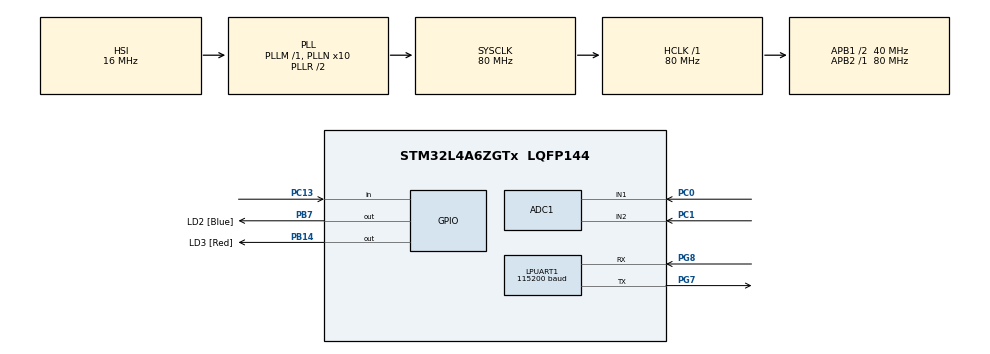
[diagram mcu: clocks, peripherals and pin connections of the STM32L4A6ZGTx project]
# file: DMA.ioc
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ADC1.Channel-2\#ChannelRegularConversion=ADC_CHANNEL_1
ADC1.ContinuousConvMode=ENABLE
ADC1.NbrOfConversionFlag=1
ADC1.OffsetNumber-2\#ChannelRegularConversion=ADC_OFFSET_NONE
ADC1.Rank-2\#ChannelRegularConversion=1
ADC1.SamplingTime-2\#ChannelRegularConversion=ADC_SAMPLETIME_2CYCLES_5
ADC1.SingleDiff-2\#ChannelRegularConversion=ADC_DIFFERENTIAL_ENDED
ADC1.master=1
Dma.ADC1.0.Direction=DMA_PERIPH_TO_MEMORY
Dma.ADC1.0.Instance=DMA1_Channel1
Dma.ADC1.0.MemDataAlignment=DMA_MDATAALIGN_HALFWORD
Dma.ADC1.0.MemInc=DMA_MINC_ENABLE
Dma.ADC1.0.Mode=DMA_NORMAL
Dma.ADC1.0.PeriphDataAlignment=DMA_PDATAALIGN_HALFWORD
Dma.ADC1.0.PeriphInc=DMA_PINC_DISABLE
Dma.ADC1.0.Priority=DMA_PRIORITY_LOW
Dma.Request0=ADC1
LPUART1.BaudRate=115200
LPUART1.WordLength=UART_WORDLENGTH_8B
Mcu.Family=STM32L4
Mcu.Name=STM32L4A6ZGTx
Mcu.Package=LQFP144
NVIC.DMA1_Channel1_IRQn=true\:0\:0\:false\:false\:true\:false\:true\:true
NVIC.PriorityGroup=NVIC_PRIORITYGROUP_4
PB14.GPIO_Label=LD3 [Red]
PB14.PinState=GPIO_PIN_SET
PB14.Signal=GPIO_Output
PB7.GPIO_Label=LD2 [Blue]
PB7.PinState=GPIO_PIN_SET
PB7.Signal=GPIO_Output
PC0.Signal=ADCx_IN1
PC1.Signal=ADCx_IN2
PC13.Signal=GPIO_Input
PC14-OSC32_IN\ (PC14).Mode=LSE-External-Oscillator
PC14-OSC32_IN\ (PC14).Signal=RCC_OSC32_IN
PC15-OSC32_OUT\ (PC15).Mode=LSE-External-Oscillator
PC15-OSC32_OUT\ (PC15).Signal=RCC_OSC32_OUT
PG7.Mode=Asynchronous
PG7.Signal=LPUART1_TX
PG8.Mode=Asynchronous
PG8.Signal=LPUART1_RX
ProjectManager.HeapSize=0x200
ProjectManager.StackSize=0x400
ProjectManager.TargetToolchain=STM32CubeIDE
RCC.ADCFreq_Value=64000000
RCC.AHBFreq_Value=80000000
RCC.APB1CLKDivider=RCC_HCLK_DIV2
RCC.APB1Freq_Value=40000000
RCC.APB1TimFreq_Value=80000000
RCC.APB2Freq_Value=80000000
RCC.APB2TimFreq_Value=80000000
RCC.CortexFreq_Value=80000000
RCC.FLatency=FLASH_LATENCY_4
RCC.HCLKFreq_Value=80000000
RCC.HSE_VALUE=8000000
RCC.HSI48_VALUE=48000000
RCC.HSI_VALUE=16000000
RCC.MSI_VALUE=4000000
RCC.PLLN=10
RCC.PLLSourceVirtual=RCC_PLLSOURCE_HSI
RCC.SYSCLKFreq_VALUE=80000000
RCC.SYSCLKSource=RCC_SYSCLKSOURCE_PLLCLK
RCC.USBFreq_Value=64000000
RCC.VCOOutputFreq_Value=160000000
SH.ADCx_IN1.0=ADC1_IN1,IN1-Differential
SH.ADCx_IN2.0=ADC1_IN2,IN1-Differential
board=NUCLEO-L4A6ZG

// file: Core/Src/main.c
#include "main.h"
#include <stdio.h>
#include <string.h>

ADC_HandleTypeDef hadc1;
DMA_HandleTypeDef hdma_adc1;
UART_HandleTypeDef hlpuart1;

/* USER CODE BEGIN PV */
uint32_t adc_values[1000];
char msg[50];
/* USER CODE END PV */

float calculate_average(uint32_t *array, size_t length) {
    uint64_t sum = 0;
    for (size_t i = 0; i < length; i++) {
        sum += array[i];
    }
    return (float)sum / length;
}

void SystemClock_Config(void);
void MX_GPIO_Init(void);
void MX_ADC1_Init(void);
void MX_LPUART1_UART_Init(void);
void MX_DMA_Init(void);

int main(void) {
    HAL_Init();
    SystemClock_Config();
    MX_GPIO_Init();
    MX_DMA_Init();
    MX_ADC1_Init();
    MX_LPUART1_UART_Init();
    sprintf(msg, "UART Initialized\r\n");
    HAL_UART_Transmit(&hlpuart1, (uint8_t*)msg, strlen(msg), HAL_MAX_DELAY);

    if (HAL_ADC_Start_DMA(&hadc1, adc_values, 1000) != HAL_OK) {
        sprintf(msg, "ADC DMA Start Error\r\n");
        HAL_UART_Transmit(&hlpuart1, (uint8_t*)msg, strlen(msg), HAL_MAX_DELAY);
        Error_Handler();
    }

    sprintf(msg, "ADC DMA Started\r\n");
    HAL_UART_Transmit(&hlpuart1, (uint8_t*)msg, strlen(msg), HAL_MAX_DELAY);

    while (1) {
        HAL_Delay(100);
    }
}

void HAL_ADC_ConvHalfCpltCallback(ADC_HandleTypeDef *hadc) {
	  sprintf(msg, "Hello\r\n");
    if (hadc->Instance == ADC1) {
        sprintf(msg, "Half conversion complete\r\n");
        HAL_UART_Transmit(&hlpuart1, (uint8_t*)msg, strlen(msg), HAL_MAX_DELAY);
    }
}

void HAL_ADC_ConvCpltCallback(ADC_HandleTypeDef *hadc) {
    if (hadc->Instance == ADC1) {
        float average = calculate_average(adc_values, 1000);

        sprintf(msg, "Conversion complete. Average: %.2f\r\n", average);
        HAL_UART_Transmit(&hlpuart1, (uint8_t*)msg, strlen(msg), HAL_MAX_DELAY);

        HAL_ADC_Start_DMA(hadc, adc_values, 1000);
    }
}
void SystemClock_Config(void)
{
  RCC_OscInitTypeDef RCC_OscInitStruct = {0};
  RCC_ClkInitTypeDef RCC_ClkInitStruct = {0};

  /** Configure the main internal regulator output voltage
  */
  if (HAL_PWREx_ControlVoltageScaling(PWR_REGULATOR_VOLTAGE_SCALE1) != HAL_OK)
  {
    Error_Handler();
  }

  /** Initializes the RCC Oscillators according to the specified parameters
  * in the RCC_OscInitTypeDef structure.
  */
  RCC_OscInitStruct.OscillatorType = RCC_OSCILLATORTYPE_HSI;
  RCC_OscInitStruct.HSIState = RCC_HSI_ON;
  RCC_OscInitStruct.HSICalibrationValue = RCC_HSICALIBRATION_DEFAULT;
  RCC_OscInitStruct.PLL.PLLState = RCC_PLL_ON;
  RCC_OscInitStruct.PLL.PLLSource = RCC_PLLSOURCE_HSI;
  RCC_OscInitStruct.PLL.PLLM = 1;
  RCC_OscInitStruct.PLL.PLLN = 10;
  RCC_OscInitStruct.PLL.PLLP = RCC_PLLP_DIV2;
  RCC_OscInitStruct.PLL.PLLQ = RCC_PLLQ_DIV2;
  RCC_OscInitStruct.PLL.PLLR = RCC_PLLR_DIV2;
  if (HAL_RCC_OscConfig(&RCC_OscInitStruct) != HAL_OK)
  {
    Error_Handler();
  }

  /** Initializes the CPU, AHB and APB buses clocks
  */
  RCC_ClkInitStruct.ClockType = RCC_CLOCKTYPE_HCLK|RCC_CLOCKTYPE_SYSCLK
                              |RCC_CLOCKTYPE_PCLK1|RCC_CLOCKTYPE_PCLK2;
  RCC_ClkInitStruct.SYSCLKSource = RCC_SYSCLKSOURCE_PLLCLK;
  RCC_ClkInitStruct.AHBCLKDivider = RCC_SYSCLK_DIV1;
  RCC_ClkInitStruct.APB1CLKDivider = RCC_HCLK_DIV2;
  RCC_ClkInitStruct.APB2CLKDivider = RCC_HCLK_DIV1;

  if (HAL_RCC_ClockConfig(&RCC_ClkInitStruct, FLASH_LATENCY_4) != HAL_OK)
  {
    Error_Handler();
  }
}

void MX_ADC1_Init(void)
{

  ADC_MultiModeTypeDef multimode = {0};
  ADC_ChannelConfTypeDef sConfig = {0};

  /** Common config
  */
  hadc1.Instance = ADC1;
  hadc1.Init.ClockPrescaler = ADC_CLOCK_ASYNC_DIV1;
  hadc1.Init.Resolution = ADC_RESOLUTION_12B;
  hadc1.Init.DataAlign = ADC_DATAALIGN_RIGHT;
  hadc1.Init.ScanConvMode = ADC_SCAN_DISABLE;
  hadc1.Init.EOCSelection = ADC_EOC_SINGLE_CONV;
  hadc1.Init.LowPowerAutoWait = DISABLE;
  hadc1.Init.ContinuousConvMode = ENABLE;
  hadc1.Init.NbrOfConversion = 1;
  hadc1.Init.DiscontinuousConvMode = DISABLE;
  hadc1.Init.ExternalTrigConv = ADC_SOFTWARE_START;
  hadc1.Init.ExternalTrigConvEdge = ADC_EXTERNALTRIGCONVEDGE_NONE;
  hadc1.Init.DMAContinuousRequests = DISABLE;
  hadc1.Init.Overrun = ADC_OVR_DATA_PRESERVED;
  hadc1.Init.OversamplingMode = DISABLE;
  if (HAL_ADC_Init(&hadc1) != HAL_OK)
  {
    Error_Handler();
  }

  /** Configure the ADC multi-mode
  */
  multimode.Mode = ADC_MODE_INDEPENDENT;
  if (HAL_ADCEx_MultiModeConfigChannel(&hadc1, &multimode) != HAL_OK)
  {
    Error_Handler();
  }

  /** Configure Regular Channel
  */
  sConfig.Channel = ADC_CHANNEL_1;
  sConfig.Rank = ADC_REGULAR_RANK_1;
  sConfig.SamplingTime = ADC_SAMPLETIME_2CYCLES_5;
  sConfig.SingleDiff = ADC_SINGLE_ENDED;
  sConfig.OffsetNumber = ADC_OFFSET_NONE;
  sConfig.Offset = 0;
  if (HAL_ADC_ConfigChannel(&hadc1, &sConfig) != HAL_OK)
  {
    Error_Handler();
  }

}

void MX_LPUART1_UART_Init(void)
{

  hlpuart1.Instance = LPUART1;
  hlpuart1.Init.BaudRate = 115200;
  hlpuart1.Init.WordLength = UART_WORDLENGTH_8B;
  hlpuart1.Init.StopBits = UART_STOPBITS_1;
  hlpuart1.Init.Parity = UART_PARITY_NONE;
  hlpuart1.Init.Mode = UART_MODE_TX_RX;
  hlpuart1.Init.HwFlowCtl = UART_HWCONTROL_NONE;
  hlpuart1.Init.OneBitSampling = UART_ONE_BIT_SAMPLE_DISABLE;
  hlpuart1.AdvancedInit.AdvFeatureInit = UART_ADVFEATURE_NO_INIT;
  if (HAL_UART_Init(&hlpuart1) != HAL_OK)
  {
    Error_Handler();
  }

}

void MX_DMA_Init(void)
{

  /* DMA controller clock enable */
  __HAL_RCC_DMA1_CLK_ENABLE();

  /* DMA interrupt init */
  /* DMA1_Channel1_IRQn interrupt configuration */
  HAL_NVIC_SetPriority(DMA1_Channel1_IRQn, 0, 0);
  HAL_NVIC_EnableIRQ(DMA1_Channel1_IRQn);

}

void MX_GPIO_Init(void)
{
  GPIO_InitTypeDef GPIO_InitStruct = {0};

  /* GPIO Ports Clock Enable */
  __HAL_RCC_GPIOC_CLK_ENABLE();
  __HAL_RCC_GPIOA_CLK_ENABLE();
  __HAL_RCC_GPIOB_CLK_ENABLE();
  __HAL_RCC_GPIOG_CLK_ENABLE();
  HAL_PWREx_EnableVddIO2();

  /*Configure GPIO pin Output Level */
  HAL_GPIO_WritePin(GPIOB, LD3_Pin|LD2_Pin, GPIO_PIN_SET);

  /*Configure GPIO pin : PC13 */
  GPIO_InitStruct.Pin = GPIO_PIN_13;
  GPIO_InitStruct.Mode = GPIO_MODE_INPUT;
  GPIO_InitStruct.Pull = GPIO_NOPULL;
  HAL_GPIO_Init(GPIOC, &GPIO_InitStruct);

  /*Configure GPIO pins : LD3_Pin LD2_Pin */
  GPIO_InitStruct.Pin = LD3_Pin|LD2_Pin;
  GPIO_InitStruct.Mode = GPIO_MODE_OUTPUT_PP;
  GPIO_InitStruct.Pull = GPIO_NOPULL;
  GPIO_InitStruct.Speed = GPIO_SPEED_FREQ_LOW;
  HAL_GPIO_Init(GPIOB, &GPIO_InitStruct);

}

void Error_Handler(void)
{
  __disable_irq();
  while (1)
  {
  }
}
